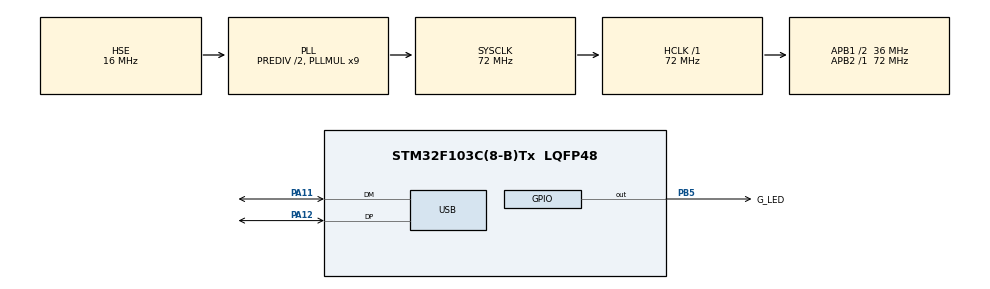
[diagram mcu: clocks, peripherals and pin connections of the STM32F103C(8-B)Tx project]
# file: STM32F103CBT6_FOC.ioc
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Mcu.Family=STM32F1
Mcu.Name=STM32F103C(8-B)Tx
Mcu.Package=LQFP48
NVIC.PriorityGroup=NVIC_PRIORITYGROUP_4
NVIC.USB_LP_CAN1_RX0_IRQn=true\:0\:0\:false\:false\:true\:true\:true\:true
PA11.Mode=Device
PA11.Signal=USB_DM
PA12.Mode=Device
PA12.Signal=USB_DP
PA13.Mode=Serial_Wire
PA13.Signal=SYS_JTMS-SWDIO
PA14.Mode=Serial_Wire
PA14.Signal=SYS_JTCK-SWCLK
PB5.GPIO_Label=G_LED
PB5.PinState=GPIO_PIN_SET
PB5.Signal=GPIO_Output
PD0-OSC_IN.Mode=HSE-External-Oscillator
PD0-OSC_IN.Signal=RCC_OSC_IN
PD1-OSC_OUT.Mode=HSE-External-Oscillator
PD1-OSC_OUT.Signal=RCC_OSC_OUT
ProjectManager.HeapSize=0x200
ProjectManager.StackSize=0x400
ProjectManager.TargetToolchain=STM32CubeIDE
RCC.AHBFreq_Value=72000000
RCC.APB1CLKDivider=RCC_HCLK_DIV2
RCC.APB1Freq_Value=36000000
RCC.APB1TimFreq_Value=72000000
RCC.APB2Freq_Value=72000000
RCC.APB2TimFreq_Value=72000000
RCC.HCLKFreq_Value=72000000
RCC.HSEDivPLL=RCC_HSE_PREDIV_DIV2
RCC.HSE_VALUE=16000000
RCC.PLLMUL=RCC_PLL_MUL9
RCC.SYSCLKFreq_VALUE=72000000
RCC.SYSCLKSource=RCC_SYSCLKSOURCE_PLLCLK
RCC.USBFreq_Value=48000000
RCC.USBPrescaler=RCC_USBCLKSOURCE_PLL_DIV1_5
board=custom

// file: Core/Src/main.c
/* USER CODE BEGIN Header */
/**
 ******************************************************************************
 * @file           : main.c
 * @brief          : Main program body
 ******************************************************************************
 * @attention
 *
 * Copyright (c) 2026 STMicroelectronics.
 * All rights reserved.
 *
 * This software is licensed under terms that can be found in the LICENSE file
 * in the root directory of this software component.
 * If no LICENSE file comes with this software, it is provided AS-IS.
 *
 ******************************************************************************
 */
/* USER CODE END Header */
#include "main.h"

/* USER CODE BEGIN Includes */
#include "tusb_config.h"
#include "tusb.h"
/* USER CODE END Includes */

PCD_HandleTypeDef hpcd_USB_FS;

void SystemClock_Config(void);
static void MX_GPIO_Init(void);
static void MX_USB_PCD_Init(void);

int main(void) {

	/* MCU Configuration--------------------------------------------------------*/

	/* Reset of all peripherals, Initializes the Flash interface and the Systick. */
	HAL_Init();

	/* Configure the system clock */
	SystemClock_Config();

	/* Initialize all configured peripherals */
	MX_GPIO_Init();
	MX_USB_PCD_Init();
	/* USER CODE BEGIN 2 */
	uint32_t currentTime = 0;
	uint32_t previousTime = 0;

	tusb_rhport_init_t dev_init = { .role = TUSB_ROLE_DEVICE, .speed =
			TUSB_SPEED_FULL };
	tusb_init(0, &dev_init);

	uint8_t rxBuf[64];
	uint32_t rxCnt, rxIdx;
	/* USER CODE END 2 */

	/* Infinite loop */
	/* USER CODE BEGIN WHILE */
	while (1) {
		//######################
		//System LED Blink
		//######################
		currentTime = HAL_GetTick();
		if (currentTime - previousTime >= 500) {
			HAL_GPIO_TogglePin(G_LED_GPIO_Port, G_LED_Pin);
			previousTime = currentTime;
		}

		tud_task();

		if (tud_cdc_n_available(0)) {
			rxCnt = tud_cdc_n_read(0, rxBuf, sizeof(rxBuf));

			for (rxIdx = 0; rxIdx < rxCnt; rxIdx++) {
				tud_cdc_n_write_char(0, rxBuf[rxIdx]);
			}

			tud_cdc_n_write_flush(0);
		}
		/* USER CODE END WHILE */

	}
}

void SystemClock_Config(void) {
	RCC_OscInitTypeDef RCC_OscInitStruct = { 0 };
	RCC_ClkInitTypeDef RCC_ClkInitStruct = { 0 };
	RCC_PeriphCLKInitTypeDef PeriphClkInit = { 0 };

	/** Initializes the RCC Oscillators according to the specified parameters
	 * in the RCC_OscInitTypeDef structure.
	 */
	RCC_OscInitStruct.OscillatorType = RCC_OSCILLATORTYPE_HSE;
	RCC_OscInitStruct.HSEState = RCC_HSE_ON;
	RCC_OscInitStruct.HSEPredivValue = RCC_HSE_PREDIV_DIV2;
	RCC_OscInitStruct.HSIState = RCC_HSI_ON;
	RCC_OscInitStruct.PLL.PLLState = RCC_PLL_ON;
	RCC_OscInitStruct.PLL.PLLSource = RCC_PLLSOURCE_HSE;
	RCC_OscInitStruct.PLL.PLLMUL = RCC_PLL_MUL9;
	if (HAL_RCC_OscConfig(&RCC_OscInitStruct) != HAL_OK) {
		Error_Handler();
	}

	/** Initializes the CPU, AHB and APB buses clocks
	 */
	RCC_ClkInitStruct.ClockType = RCC_CLOCKTYPE_HCLK | RCC_CLOCKTYPE_SYSCLK
			| RCC_CLOCKTYPE_PCLK1 | RCC_CLOCKTYPE_PCLK2;
	RCC_ClkInitStruct.SYSCLKSource = RCC_SYSCLKSOURCE_PLLCLK;
	RCC_ClkInitStruct.AHBCLKDivider = RCC_SYSCLK_DIV1;
	RCC_ClkInitStruct.APB1CLKDivider = RCC_HCLK_DIV2;
	RCC_ClkInitStruct.APB2CLKDivider = RCC_HCLK_DIV1;

	if (HAL_RCC_ClockConfig(&RCC_ClkInitStruct, FLASH_LATENCY_2) != HAL_OK) {
		Error_Handler();
	}
	PeriphClkInit.PeriphClockSelection = RCC_PERIPHCLK_USB;
	PeriphClkInit.UsbClockSelection = RCC_USBCLKSOURCE_PLL_DIV1_5;
	if (HAL_RCCEx_PeriphCLKConfig(&PeriphClkInit) != HAL_OK) {
		Error_Handler();
	}
}

static void MX_USB_PCD_Init(void) {

	/* USER CODE BEGIN USB_Init 0 */

	/*
	 * Force host to re-enumerate device
	 */
	GPIO_InitTypeDef GPIO_InitStruct = { 0 };              // All zeroed out
	GPIO_InitStruct.Pin = GPIO_PIN_12;           // Hardcoding this - PA12 is D+
	GPIO_InitStruct.Mode = GPIO_MODE_OUTPUT_PP;            // Push-pull mode
	GPIO_InitStruct.Pull = GPIO_PULLDOWN;               // Resetting so pull low
	GPIO_InitStruct.Speed = GPIO_SPEED_HIGH; // Really shouldn't matter in this case
	HAL_GPIO_Init(GPIOA, &GPIO_InitStruct);    // Initialize with above settings
	HAL_GPIO_WritePin(GPIOA, GPIO_PIN_12, GPIO_PIN_RESET); // Yank low
	HAL_Delay(50);                  // Enough time for host to disconnect device
	HAL_GPIO_WritePin(GPIOA, GPIO_PIN_12, GPIO_PIN_SET); // Back high - so host will enumerate
	HAL_GPIO_DeInit(GPIOA, GPIO_PIN_12);                 // Deinitialize the pin

	/* USER CODE END USB_Init 0 */

	hpcd_USB_FS.Instance = USB;
	hpcd_USB_FS.Init.dev_endpoints = 8;
	hpcd_USB_FS.Init.speed = PCD_SPEED_FULL;
	hpcd_USB_FS.Init.low_power_enable = DISABLE;
	hpcd_USB_FS.Init.lpm_enable = DISABLE;
	hpcd_USB_FS.Init.battery_charging_enable = DISABLE;
	if (HAL_PCD_Init(&hpcd_USB_FS) != HAL_OK) {
		Error_Handler();
	}

}

static void MX_GPIO_Init(void) {
	GPIO_InitTypeDef GPIO_InitStruct = { 0 };

	/* GPIO Ports Clock Enable */
	__HAL_RCC_GPIOD_CLK_ENABLE();
	__HAL_RCC_GPIOA_CLK_ENABLE();
	__HAL_RCC_GPIOB_CLK_ENABLE();

	/*Configure GPIO pin Output Level */
	HAL_GPIO_WritePin(G_LED_GPIO_Port, G_LED_Pin, GPIO_PIN_SET);

	/*Configure GPIO pin : G_LED_Pin */
	GPIO_InitStruct.Pin = G_LED_Pin;
	GPIO_InitStruct.Mode = GPIO_MODE_OUTPUT_PP;
	GPIO_InitStruct.Pull = GPIO_NOPULL;
	GPIO_InitStruct.Speed = GPIO_SPEED_FREQ_LOW;
	HAL_GPIO_Init(G_LED_GPIO_Port, &GPIO_InitStruct);

}

void Error_Handler(void) {
	__disable_irq();
	while (1) {
	}
}
